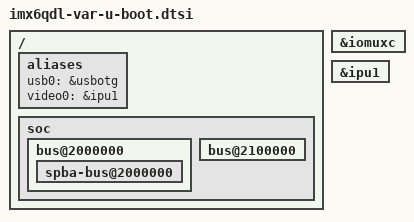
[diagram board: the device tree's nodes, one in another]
// SPDX-License-Identifier: GPL-2.0+
/*
 * Copyright (C) 2018 Jagan Teki <jagan@amarulasolutions.com>
 * Copyright (C) 2024 Variscite Ltd.
 */

/ {
	aliases {
		usb0 = &usbotg;
		video0 = &ipu1;
	};

	soc {
		bootph-pre-ram;
		bootph-all;

		bus@2000000 {
			bootph-pre-ram;
			spba-bus@2000000 {
				bootph-pre-ram;
			};
		};

		bus@2100000 {
			bootph-pre-ram;
		};
	};
};

&iomuxc {
	bootph-pre-ram;
};

&ipu1 {
	bootph-all;
};
